# TESTDEVICE register map
File version: 1.0
Fixture device
Registers are 32-bit, access not given, no defined reset value unless marked. A register's access mark holds for its fields unless they carry their own. Offsets are from the block's base; lines under a group give offsets from that group; [hi:lo] are bit positions; {n}, {i} and the like mark numbered series; 'fields as' and 'values as' point back to an identical list; <NAME> marks a mode.

## Memory map
0x40000000 TIM2 — General purpose timer
0x40005400 I2C1 size 0x400 — Inter-integrated circuit
0x40020000 GPIOA size 0x400 — General-purpose I/Os
0x40020400 GPIOB size 0x400
0x40023800 RCC size 0x400 — Reset and clock control

## RCC — Reset and clock control
Base 0x40023800
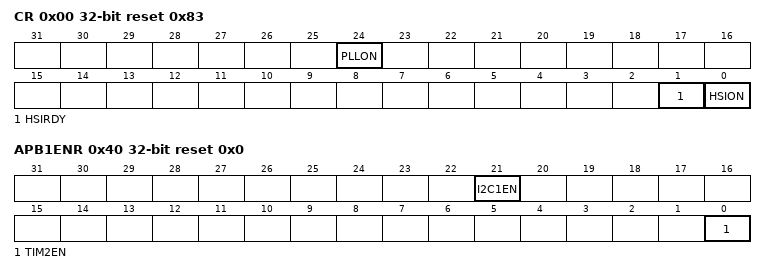
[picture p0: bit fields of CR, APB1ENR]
0x00 CR rw reset 0x83 — Clock control register
  [24] PLLON — Main PLL enable
  [1] HSIRDY ro — Internal high-speed clock ready
  [0] HSION — Internal high-speed clock enable
    0=Off (Clock off); 1=On (Clock on)
0x40 APB1ENR reset 0x0 — APB1 peripheral clock enable register
  [21] I2C1EN — I2C1 clock enable
  [0] TIM2EN — TIM2 clock enable
    0=Disabled (Clock gated); 1=Enabled (Clock running)

## GPIOA — General-purpose I/Os
Base 0x40020000
Same registers: GPIOB 0x40020400
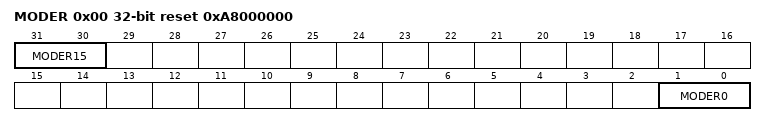
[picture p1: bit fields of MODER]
0x00 MODER reset 0xA8000000 — Port mode register
  [31:30] MODER15, [1:0] MODER0
0x14 ODR — Port output data register
  [0] ODR0
{0x20+4i} AFR{i} (i=0..3) — Alternate function register {i}
0x30 BSRR{x} (x=L,H; step 0x4) — Bit set/reset register, {x} half

## TIM2 — General purpose timer
Base 0x40000000
0x24 CNT — Counter
{0x30+4i} CCR{i} (i=1..4) — Capture/compare register {i}
  [15:0] CCR — Capture/compare value

## I2C1 — Inter-integrated circuit
Base 0x40005400
0x00 CR1 — Control register 1
  [0] PE — Peripheral enable
